# M2Sxxx register map
Vendor: Microsemi; Series: SmartFusion2; File version: 2.0.32
CPU: CM3 r2p1, little endian, MPU, no FPU, 4 interrupt priority bits
Registers are 32-bit, read-write, no defined reset value unless marked. A register's access mark holds for its fields unless they carry their own. Offsets are from the block's base; [hi:lo] are bit positions; {n}, {i} and the like mark numbered series.

## AHB_to_eNVM_0 — No description provided for this peripheral
Base 0x60080000
{0x0+4i} ENVM0_ASSEMBLY_BUFFER_{i} (i=0..31) — No description provided for this register
  [31:0] RD_DATA_ASSEM_BUFF_{i} ro — No description provided for this field
{0x80+4i} ENVM0_WD_BUFFER_{i} (i=0..31) — No description provided for this register
  [31:0] WR_DATA_BUFF_{i} — No description provided for this field
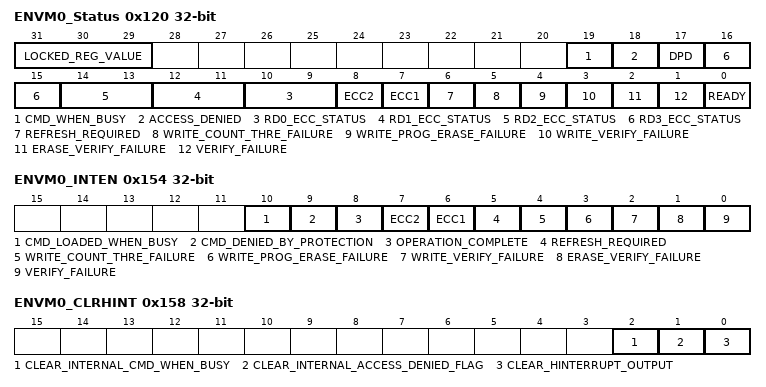
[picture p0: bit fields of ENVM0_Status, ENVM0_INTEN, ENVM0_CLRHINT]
0x120 ENVM0_Status — No description provided for this register
  [31:29] LOCKED_REG_VALUE ro — No description provided for this field
  [19] CMD_WHEN_BUSY ro — No description provided for this field
  [18] ACCESS_DENIED ro — No description provided for this field
  [17] DPD ro — No description provided for this field
  [2n+10:2n+9] RD{n}_ECC_STATUS ro (n=0..3) — No description provided for this field
  [8] ECC2 ro — No description provided for this field
  [7] ECC1 ro — No description provided for this field
  [6] REFRESH_REQUIRED ro — No description provided for this field
  [5] WRITE_COUNT_THRE_FAILURE ro — No description provided for this field
  [4] WRITE_PROG_ERASE_FAILURE ro — No description provided for this field
  [3] WRITE_VERIFY_FAILURE ro — No description provided for this field
  [2] ERASE_VERIFY_FAILURE ro — No description provided for this field
  [1] VERIFY_FAILURE ro — No description provided for this field
  [0] READY ro — No description provided for this field
0x128 ENVM0_PAGE_STATUS — No description provided for this register
  [0] STATUS — No description provided for this field
0x12C ENVM0_FREQRNG — No description provided for this register
  [3:0] FREQRNG ro — No description provided for this field
0x130 ENVM0_DPD — No description provided for this register
  [0] DPD ro — No description provided for this field
0x134 ENVM0_ENB_CACHE — No description provided for this register
  [0] NV_CE — No description provided for this field
0x140 ENVM0_PAGE_LOCK_SET — No description provided for this register
  [0] PAGELOCKBIT — No description provided for this field
0x144 ENVM0_DWSIZE — No description provided for this register
  [3:0] DWSIZE — No description provided for this field
0x148 ENVM0_CMD — No description provided for this register
  [31:0] CMD wo — No description provided for this field
0x154 ENVM0_INTEN — No description provided for this register
  [10] CMD_LOADED_WHEN_BUSY — No description provided for this field
  [9] CMD_DENIED_BY_PROTECTION — No description provided for this field
  [8] OPERATION_COMPLETE — No description provided for this field
  [7] ECC2 — No description provided for this field
  [6] ECC1 — No description provided for this field
  [5] REFRESH_REQUIRED — No description provided for this field
  [4] WRITE_COUNT_THRE_FAILURE — No description provided for this field
  [3] WRITE_PROG_ERASE_FAILURE — No description provided for this field
  [2] WRITE_VERIFY_FAILURE — No description provided for this field
  [1] ERASE_VERIFY_FAILURE — No description provided for this field
  [0] VERIFY_FAILURE — No description provided for this field
0x158 ENVM0_CLRHINT — No description provided for this register
  [2] CLEAR_INTERNAL_CMD_WHEN_BUSY — No description provided for this field
  [1] CLEAR_INTERNAL_ACCESS_DENIED_FLAG — No description provided for this field
  [0] CLEAR_HINTERRUPT_OUTPUT — No description provided for this field
0x1FC ENVM0_REQACCESS — No description provided for this register
  [2:0] RRA — No description provided for this field

## AHB_to_eNVM_1 — No description provided for this peripheral
Base 0x600C0000
{0x0+4i} ENVM1_ASSEMBLY_BUFFER_{i} (i=0..31) — No description provided for this register
  [31:0] RD_DATA_ASSEM_BUFF_{i} ro — No description provided for this field
{0x80+4i} ENVM1_WD_BUFFER_{i} (i=0..31) — No description provided for this register
  [31:0] WR_DATA_BUFF_{i} — No description provided for this field
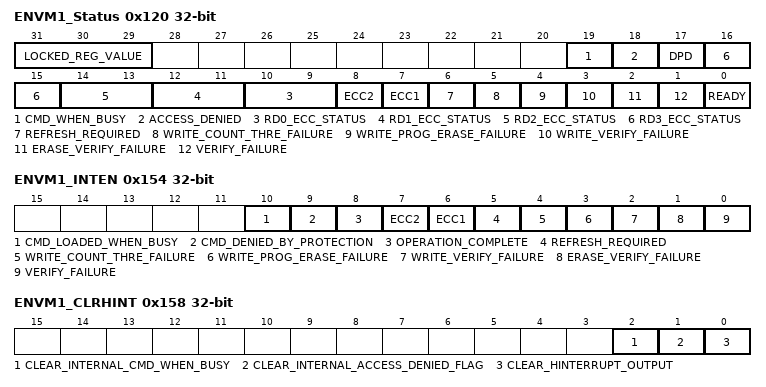
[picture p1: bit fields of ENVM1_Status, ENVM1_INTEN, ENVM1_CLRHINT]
0x120 ENVM1_Status — No description provided for this register
  [31:29] LOCKED_REG_VALUE ro — No description provided for this field
  [19] CMD_WHEN_BUSY ro — No description provided for this field
  [18] ACCESS_DENIED ro — No description provided for this field
  [17] DPD ro — No description provided for this field
  [2n+10:2n+9] RD{n}_ECC_STATUS ro (n=0..3) — No description provided for this field
  [8] ECC2 ro — No description provided for this field
  [7] ECC1 ro — No description provided for this field
  [6] REFRESH_REQUIRED ro — No description provided for this field
  [5] WRITE_COUNT_THRE_FAILURE ro — No description provided for this field
  [4] WRITE_PROG_ERASE_FAILURE ro — No description provided for this field
  [3] WRITE_VERIFY_FAILURE ro — No description provided for this field
  [2] ERASE_VERIFY_FAILURE ro — No description provided for this field
  [1] VERIFY_FAILURE ro — No description provided for this field
  [0] READY ro — No description provided for this field
0x128 ENVM1_PAGE_STATUS — No description provided for this register
  [0] STATUS — No description provided for this field
0x12C ENVM1_FREQRNG — No description provided for this register
  [3:0] FREQRNG ro — No description provided for this field
0x130 ENVM1_DPD — No description provided for this register
  [0] DPD ro — No description provided for this field
0x134 ENVM1_ENB_CACHE — No description provided for this register
  [0] NV_CE — No description provided for this field
0x140 ENVM1_PAGE_LOCK_SET — No description provided for this register
  [0] PAGELOCKBIT — No description provided for this field
0x144 ENVM1_DWSIZE — No description provided for this register
  [3:0] DWSIZE — No description provided for this field
0x148 ENVM1_CMD — No description provided for this register
  [31:0] CMD wo — No description provided for this field
0x154 ENVM1_INTEN — No description provided for this register
  [10] CMD_LOADED_WHEN_BUSY — No description provided for this field
  [9] CMD_DENIED_BY_PROTECTION — No description provided for this field
  [8] OPERATION_COMPLETE — No description provided for this field
  [7] ECC2 — No description provided for this field
  [6] ECC1 — No description provided for this field
  [5] REFRESH_REQUIRED — No description provided for this field
  [4] WRITE_COUNT_THRE_FAILURE — No description provided for this field
  [3] WRITE_PROG_ERASE_FAILURE — No description provided for this field
  [2] WRITE_VERIFY_FAILURE — No description provided for this field
  [1] ERASE_VERIFY_FAILURE — No description provided for this field
  [0] VERIFY_FAILURE — No description provided for this field
0x158 ENVM1_CLRHINT — No description provided for this register
  [2] CLEAR_INTERNAL_CMD_WHEN_BUSY — No description provided for this field
  [1] CLEAR_INTERNAL_ACCESS_DENIED_FLAG — No description provided for this field
  [0] CLEAR_HINTERRUPT_OUTPUT — No description provided for this field
0x1FC ENVM1_REQACCESS — No description provided for this register
  [2:0] RRA — No description provided for this field

## Timer — No description provided for this peripheral
Base 0x40004000
0x00 TIM1VALUE — No description provided for this register
  [31:0] TIM1VALUE ro — No description provided for this field
0x04 TIM1LOADVAL — No description provided for this register
  [31:0] TIM1LOADVAL — No description provided for this field
0x08 TIM1BGLOADVAL — No description provided for this register
  [31:0] TIM1BGLOADVAL — No description provided for this field
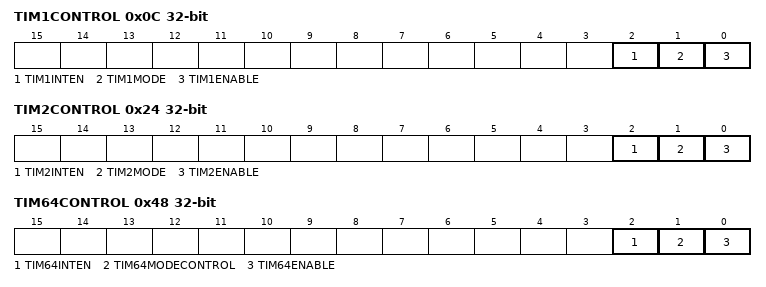
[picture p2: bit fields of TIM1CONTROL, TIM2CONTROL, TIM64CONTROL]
0x0C TIM1CONTROL — No description provided for this register
  [2] TIM1INTEN — No description provided for this field
  [1] TIM1MODE — No description provided for this field
  [0] TIM1ENABLE — No description provided for this field
0x10 TIM1RIS — No description provided for this register
  [0] TIM1RIS — No description provided for this field
0x14 TIM1MIS — No description provided for this register
  [0] TIM1MIS ro — No description provided for this field
0x18 TIM2VALUE — No description provided for this register
  [31:0] TIM2VALUE ro — No description provided for this field
0x1C TIM2LOADVAL — No description provided for this register
  [31:0] TIM2LOADVAL — No description provided for this field
0x20 TIM2BGLOADVAL — No description provided for this register
  [31:0] TIM2BGLOADVAL — No description provided for this field
0x24 TIM2CONTROL — No description provided for this register
  [2] TIM2INTEN — No description provided for this field
  [1] TIM2MODE — No description provided for this field
  [0] TIM2ENABLE — No description provided for this field
0x28 TIM2RIS — No description provided for this register
  [0] TIM2RIS — No description provided for this field
0x2C TIM2MIS — No description provided for this register
  [0] TIM2MIS ro — No description provided for this field
0x30 TIM64VALUEU — No description provided for this register
  [31:0] TIM64VALUEU ro — No description provided for this field
0x34 TIM64VALUEL — No description provided for this register
  [31:0] TIM64VALUEL ro — No description provided for this field
0x38 TIM64LOADVALU — No description provided for this register
  [31:0] TIM64LOADVALU — No description provided for this field
0x3C TIM64LOADVALL — No description provided for this register
  [31:0] TIM64LOADVALL — No description provided for this field
0x40 TIM64BGLOADVALU — No description provided for this register
  [31:0] TIM64BGLOADVALU — No description provided for this field
0x44 TIM64BGLOADVALL — No description provided for this register
  [31:0] TIM64BGLOADVALL — No description provided for this field
0x48 TIM64CONTROL — No description provided for this register
  [2] TIM64INTEN — No description provided for this field
  [1] TIM64MODECONTROL — No description provided for this field
  [0] TIM64ENABLE — No description provided for this field
0x4C TIM64RIS — No description provided for this register
  [0] TIM64RIS — No description provided for this field
0x50 TIM64MIS — No description provided for this register
  [0] TIM64MIS ro — No description provided for this field
0x54 TIM64MODE — No description provided for this register
  [0] TIM64MODE — No description provided for this field
